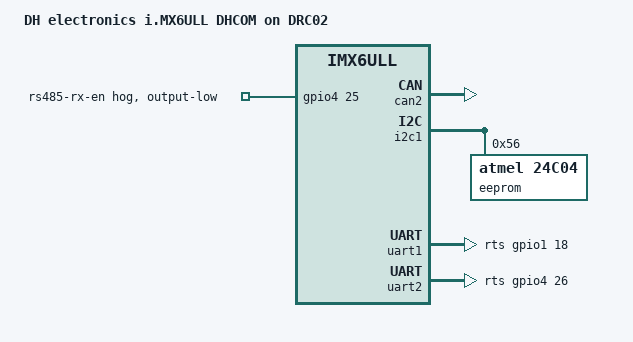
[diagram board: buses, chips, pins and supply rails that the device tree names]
/dts-v1/;
#include "imx6ull-dhcom-som.dtsi"
#include "imx6ull-dhcom-som-cfg-sdcard.dtsi"
/ {
	model = "DH electronics i.MX6ULL DHCOM on DRC02";
	compatible = "dh,imx6ull-dhcom-drc02", "dh,imx6ull-dhcom-som",
		     "dh,imx6ull-dhcor-som", "fsl,imx6ull";
};
&can2 {
	status = "okay";
};
&gpio1 {
	gpio-line-names =
		"", "", "", "",
		"", "", "", "",
		"", "", "", "DRC02-In2",
		"", "", "", "",
		"", "", "DHCOM-I", "",
		"", "", "", "",
		"", "", "", "",
		"", "", "", "";
};
&gpio4 {
	gpio-line-names =
		"", "", "", "",
		"", "", "", "",
		"", "", "", "",
		"", "", "", "",
		"", "DRC02-HW0", "DRC02-HW1", "DHCOM-M",
		"DRC02-HW2", "DHCOM-U", "DHCOM-T", "DHCOM-S",
		"DHCOM-R", "DHCOM-Q", "DHCOM-P", "DHCOM-O",
		"DHCOM-N", "", "", "";
	rs485-rx-en-hog {
		gpio-hog;
		gpios = <25 0>;  
		line-name = "rs485-rx-en";
		output-low;
	};
};
&gpio5 {
	gpio-line-names =
		"DHCOM-A", "DHCOM-B", "DHCOM-C", "DRC02-Out2",
		"DHCOM-E", "", "", "DRC02-Out1",
		"DRC02-In1", "DHCOM-H", "", "",
		"", "", "", "",
		"", "", "", "",
		"", "", "", "",
		"", "", "", "",
		"", "", "", "";
};
&i2c1 {
	eeprom@56 {
		compatible = "atmel,24c04";
		reg = <0x56>;
		pagesize = <16>;
	};
};
&uart1 {
	/delete-property/ uart-has-rtscts;
	rts-gpios = <&gpio1 18 GPIO_ACTIVE_HIGH>;  
	cts-gpios = <&gpio4 19 GPIO_ACTIVE_HIGH>;  
};
&uart2 {
	/delete-property/ uart-has-rtscts;
	linux,rs485-enabled-at-boot-time;
	rts-gpios = <&gpio4 26 GPIO_ACTIVE_HIGH>;  
};
